VERSION "Honeywell TARS-HCASS"

NS_ :

BS_:

BU_: Honeywell ADS

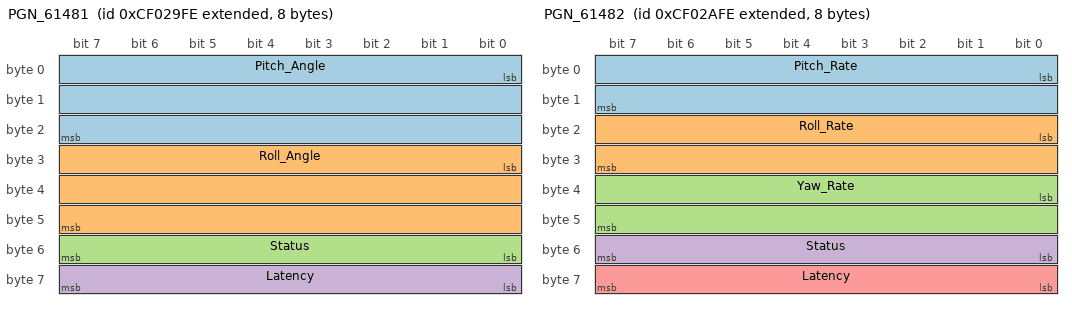
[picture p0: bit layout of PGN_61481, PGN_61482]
BO_ 2364549630 PGN_61481: 8 Honeywell
 SG_ Pitch_Angle : 0|24@1+ (3.0517578125E-005,-250) [-250|261.999969482422] "deg"  ADS
 SG_ Roll_Angle : 24|24@1+ (3.0517578125E-005,-250) [-250|261.999969482422] "deg"  ADS
 SG_ Status : 48|8@1+ (1,0) [0|255] ""  ADS
 SG_ Latency : 56|8@1+ (0.5,0) [0|127.5] "ms"  ADS

BO_ 2364549886 PGN_61482: 8 Honeywell
 SG_ Pitch_Rate : 0|16@1+ (0.0078125,-250) [-250|261.9921875] "deg/s"  ADS
 SG_ Roll_Rate : 16|16@1+ (0.0078125,-250) [-250|261.9921875] "deg/s"  ADS
 SG_ Yaw_Rate : 32|16@1+ (0.0078125,-250) [-250|261.9921875] "deg/s"  ADS
 SG_ Status : 48|8@1+ (1,0) [0|255] ""  ADS
 SG_ Latency : 56|8@1+ (0.5,0) [0|127.5] "ms"  ADS

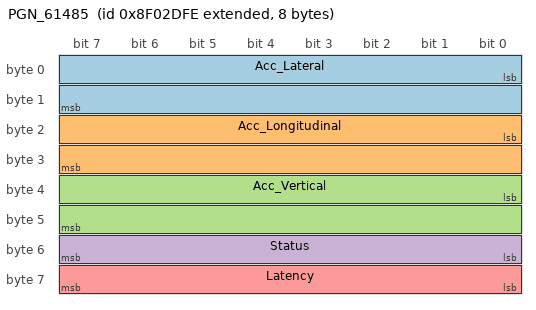
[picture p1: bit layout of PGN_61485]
BO_ 2297441790 PGN_61485: 8 Honeywell
 SG_ Acc_Lateral : 0|16@1+ (0.01,-320) [-320|335.35] "m/s^2"  ADS
 SG_ Acc_Longitudinal : 16|16@1+ (0.01,-320) [-320|335.35] "m/s^2"  ADS
 SG_ Acc_Vertical : 32|16@1+ (0.01,-320) [-320|335.35] "m/s^2"  ADS
 SG_ Status : 48|8@1+ (1,0) [0|255] ""  ADS
 SG_ Latency : 56|8@1+ (0.5,0) [0|127.5] "ms"  ADS

BA_DEF_ SG_  "SigType" ENUM  "Default","Range","RangeSigned","ASCII","Discrete","Control","ReferencePGN","DTC","StringDelimiter","StringLength","StringLengthControl","MessageCounter","MessageChecksum";
BA_DEF_ SG_  "GenSigEVName" STRING ;
BA_DEF_ SG_  "GenSigILSupport" ENUM  "No","Yes";
BA_DEF_ SG_  "GenSigSendType" ENUM  "Cyclic","OnWrite","OnWriteWithRepetition","OnChange","OnChangeWithRepetition","IfActive","IfActiveWithRepetition","NoSigSendType";
BA_DEF_ SG_  "GenSigStartValue" INT 0 2147483647;
BA_DEF_ BO_  "GenMsgILSupport" ENUM  "No","Yes";
BA_DEF_ BU_  "NmStationAddress" INT 0 255;
BA_DEF_ BO_  "GenMsgSendType" ENUM  "cyclic","NotUsed","IfActive","NotUsed","NotUsed","NotUsed","NotUsed","NotUsed","noMsgSendType";
BA_DEF_ BO_  "GenMsgRequestable" INT 0 1;
BA_DEF_  "DBName" STRING ;
BA_DEF_  "BusType" STRING ;
BA_DEF_  "ProtocolType" STRING ;
BA_DEF_ BO_  "VFrameFormat" ENUM  "StandardCAN","ExtendedCAN","reserved","J1939PG";
BA_DEF_DEF_  "SigType" "Default";
BA_DEF_DEF_  "GenSigEVName" "Env@Nodename_@Signame";
BA_DEF_DEF_  "GenSigILSupport" "Yes";
BA_DEF_DEF_  "GenSigSendType" "NoSigSendType";
BA_DEF_DEF_  "GenSigStartValue" 0;
BA_DEF_DEF_  "GenMsgILSupport" "Yes";
BA_DEF_DEF_  "NmStationAddress" 254;
BA_DEF_DEF_  "GenMsgSendType" "noMsgSendType";
BA_DEF_DEF_  "GenMsgRequestable" 1;
BA_DEF_DEF_  "DBName" "";
BA_DEF_DEF_  "BusType" "CAN";
BA_DEF_DEF_  "ProtocolType" "J1939";
BA_DEF_DEF_  "VFrameFormat" "J1939PG";
BA_ "DBName" "HW_TARS";
BA_ "GenSigStartValue" SG_ 2364549630 Pitch_Angle 8192000;
BA_ "GenSigStartValue" SG_ 2364549630 Roll_Angle 8192000;
BA_ "GenSigStartValue" SG_ 2364549886 Pitch_Rate 32000;
BA_ "GenSigStartValue" SG_ 2364549886 Roll_Rate 32000;
BA_ "GenSigStartValue" SG_ 2364549886 Yaw_Rate 32000;
BA_ "GenSigStartValue" SG_ 2297441790 Acc_Lateral 32000;
BA_ "GenSigStartValue" SG_ 2297441790 Acc_Longitudinal 32000;
BA_ "GenSigStartValue" SG_ 2297441790 Acc_Vertical 32000;
